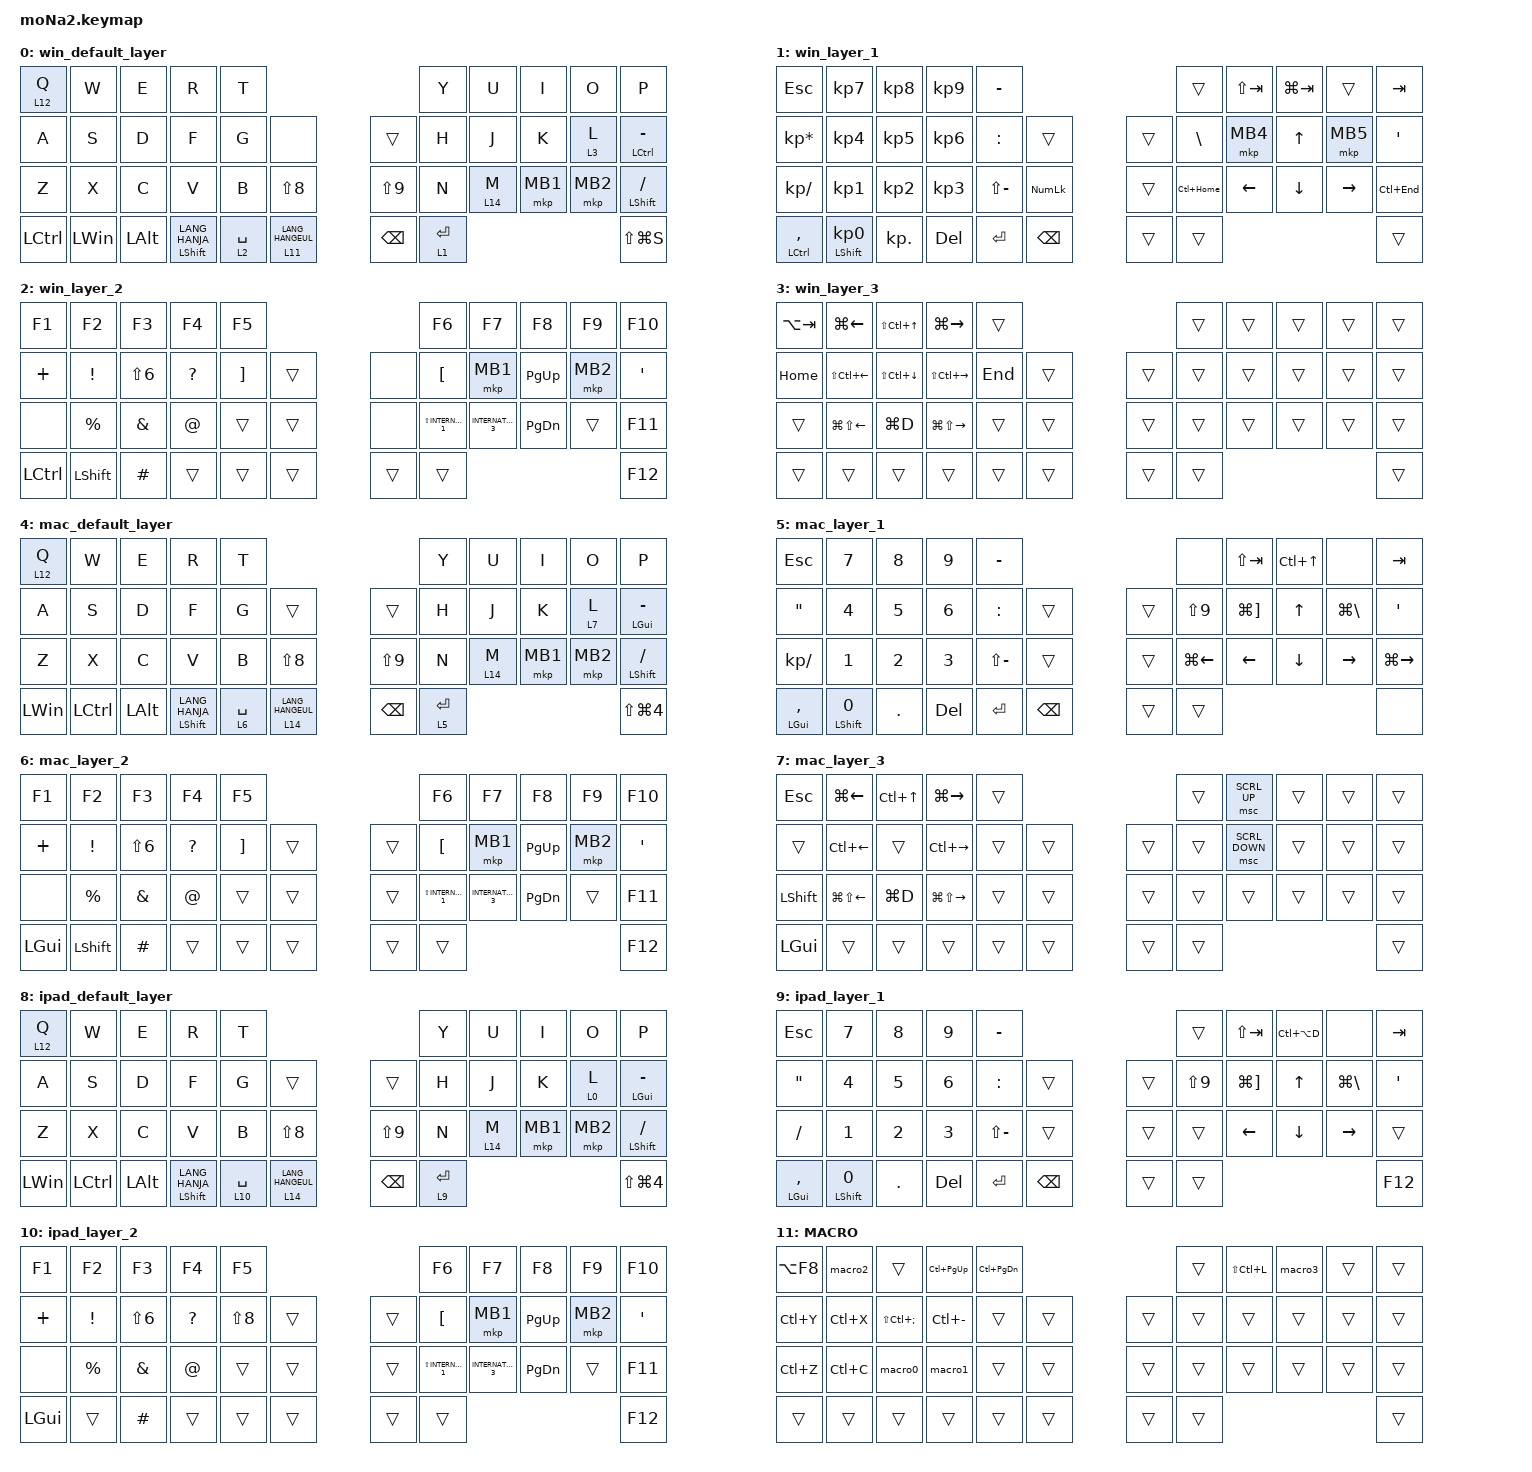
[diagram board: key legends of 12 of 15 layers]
//#include "layout_shift.dtsi"

#include <layout_shift_kp_override.dtsi>
#include <behaviors.dtsi>
#include <dt-bindings/zmk/bt.h>
#include <dt-bindings/zmk/keys.h>
#include <dt-bindings/zmk/pointing.h>

#define ZMK_POINTING_DEFAULT_SCRL_VAL 100
#define MOUSE 13

&mt {
    flavor = "balanced";
    quick-tap-ms = <0>;
};

&sl { release-after-ms = <250>; }; // ダブルクリックに必要な時間を設定
/ {
    combos {
        compatible = "zmk,combos";

        alt+ctrl+del {
            bindings = <&kp LA(LC(DELETE))>;
            key-positions = <41 9>;
        };

        left_click {
            bindings = <&mkp LCLK>;
            key-positions = <18 19>;
        };

        right_click {
            bindings = <&mkp RCLK>;
            key-positions = <20 18>;
        };

        comma {
            bindings = <&kp COMMA>;
            key-positions = <30 31>;
        };

        period {
            bindings = <&kp PERIOD>;
            key-positions = <31 32>;
        };
    };

    macros {
        to_layer_0: to_layer_0 {
            compatible = "zmk,behavior-macro-one-param";
            #binding-cells = <1>;
            bindings = <&to 0 &macro_param_1to1 &kp MACRO_PLACEHOLDER>;
            label = "TO_LAYER_0";
        };

        macro0: macro0 {
            compatible = "zmk,behavior-macro";
            #binding-cells = <0>;
            bindings = <&kp LA(LC(V)) &kp V &kp ENTER>;
            label = "MACRO1";
        };

        macro1: macro1 {
            compatible = "zmk,behavior-macro";
            #binding-cells = <0>;
            bindings = <&kp LA(H) &kp M &kp C &kp ENTER>;
            label = "MACRO2";
        };

        macro2: macro2 {
            compatible = "zmk,behavior-macro";
            #binding-cells = <0>;
            bindings = <&kp LC(G) &kp LA(S) &kp K &kp ENTER>;
            label = "MACRO3";
        };

        macro3: macro3 {
            compatible = "zmk,behavior-macro";
            #binding-cells = <0>;
            bindings = <&kp LEFT_ALT &kp D &kp F &kp S>;
            label = "MACRO0";
        };

        mkp_exit_AML: mkp_exit_AML {
            compatible = "zmk,behavior-macro-one-param";
            #binding-cells = <1>;
            bindings =
                <&macro_press>,
                <&macro_param_1to1 &mkp MACRO_PLACEHOLDER>,
                <&macro_pause_for_release>,
                <&macro_release>,
                <&macro_param_1to1 &mkp MACRO_PLACEHOLDER>,
                <&macro_tap>,
                <&sl 13>;

            label = "MKP_EXIT_AML";
        };

        bt0: bt0 {
            compatible = "zmk,behavior-macro";
            #binding-cells = <0>;
            bindings =
                <&tog_off 4 &tog_off 8>,
                <&macro_wait_time 200>,
                <&bt BT_SEL 0>,
                <&macro_wait_time 500>,
                <&bt BT_DISC 1 &bt BT_DISC 2>;

            label = "BT0";
        };

        bt1: bt1 {
            compatible = "zmk,behavior-macro";
            #binding-cells = <0>;
            bindings =
                <&tog_off 0 &tog_off 4 &tog_off 8>,
                <&macro_wait_time 200>,
                <&bt BT_SEL 1>,
                <&macro_wait_time 500>,
                <&tog_on 4 &bt BT_DISC 0 &bt BT_DISC 2>;

            label = "BT1";
        };

        bt2: bt2 {
            compatible = "zmk,behavior-macro";
            #binding-cells = <0>;
            bindings =
                <&tog_off 0 &tog_off 4 &tog_off 8>,
                <&macro_wait_time 200>,
                <&bt BT_SEL 2>,
                <&macro_wait_time 500>,
                <&tog_on 8 &bt BT_DISC 0 &bt BT_DISC 1>;

            label = "BT2";
        };

        macro4_copy_lay15: macro_4 {
            compatible = "zmk,behavior-macro";
            #binding-cells = <0>;
            bindings = <&kp LS(LC(DOWN_ARROW)) &kp LS(LC(RIGHT_ARROW)) &kp LS(LC(RIGHT_ARROW)) &kp LC(C)>;
            label = "MACRO_4";
        };

        macro_5_copy_lay15: macro_5 {
            compatible = "zmk,behavior-macro";
            #binding-cells = <0>;
            bindings = <&kp LS(LC(RIGHT_ARROW)) &kp LS(LC(RIGHT_ARROW)) &kp LC(C)>;
            label = "MACRO_5";
        };

        macro_6_ketsugou_lay15: macro_6 {
            compatible = "zmk,behavior-macro";
            #binding-cells = <0>;
            bindings = <&kp LS(LC(DOWN_ARROW)) &kp LA(H) &kp M &kp C &kp ENTER>;
            label = "MACRO_6";
        };
    };

    behaviors {
        lt_to_layer_0: lt_to_layer_0 {
            compatible = "zmk,behavior-hold-tap";
            label = "LAYER_TAP_TO_0";
            bindings = <&mo>, <&to_layer_0>;

            #binding-cells = <2>;
            tapping-term-ms = <200>;
        };

        scroll_up_down: behavior_sensor_rotate_mouse_wheel_up_down {
            compatible = "zmk,behavior-sensor-rotate";
            #sensor-binding-cells = <0>;
            bindings = <&msc SCRL_DOWN>, <&msc SCRL_UP>;

            tap-ms = <20>;
        };

        scroll_right_left: mouse_wheel_right_left {
            compatible = "zmk,behavior-sensor-rotate";
            #sensor-binding-cells = <0>;
            bindings = <&msc SCRL_LEFT>, <&msc SCRL_RIGHT>;

            tap-ms = <20>;
        };

        tog_on: toggle_layer_on_only {
            compatible = "zmk,behavior-toggle-layer";
            #binding-cells = <1>;
            display-name = "Toggle Layer On";
            toggle-mode = "on";
        };

        tog_off: toggle_layer_off_only {
            compatible = "zmk,behavior-toggle-layer";
            #binding-cells = <1>;
            display-name = "Toggle Layer Off";
            toggle-mode = "off";
        };

        // Keep the original key_press behavior for ZMK core components

        original_key_press: original_key_press {
            compatible = "zmk,behavior-key-press";
            #binding-cells = <1>;
            label = "KEY_PRESS";
        };

        // Override the existing &kp behavior to use our custom implementation

        kp: key_press {
            compatible = "zmk,behavior-layout-shift-key-press";
            #binding-cells = <1>;
            label = "LAYOUT_SHIFT_KEY_PRESS";
        };

        // Layout shift toggle behaviors

        tog_ls: toggle_layout_shift {
            compatible = "zmk,behavior-layout-shift-toggle";
            #binding-cells = <0>;
            toggle-mode = "flip";
            label = "LAYOUT_SHIFT_TOGGLE";
        };

        tog_ls_on: toggle_layout_shift_on {
            compatible = "zmk,behavior-layout-shift-toggle";
            #binding-cells = <0>;
            toggle-mode = "on";
            label = "LAYOUT_SHIFT_TOGGLE_ON";
        };

        tog_ls_off: toggle_layout_shift_off {
            compatible = "zmk,behavior-layout-shift-toggle";
            #binding-cells = <0>;
            toggle-mode = "off";
            label = "LAYOUT_SHIFT_TOGGLE_OFF";
        };
    };

    keymap {
        compatible = "zmk,keymap";

        win_default_layer {
            bindings = <
&lt 12 Q   &kp W         &kp E         &kp R                      &kp T                                                         &kp Y        &kp U     &kp I     &kp O     &kp P
&kp A      &kp S         &kp D         &kp F                      &kp G        &none                             &trans         &kp H        &kp J     &kp K     &lt 3 L   &mt LCTRL MINUS
&kp Z      &kp X         &kp C         &kp V                      &kp B        &kp LS(N8)                        &kp LS(N9)     &kp N        &lt 14 M  &mkp MB1  &mkp MB2  &mt LEFT_SHIFT SLASH
&kp LCTRL  &kp LEFT_WIN  &kp LEFT_ALT  &mt LEFT_SHIFT LANG_HANJA  &lt 2 SPACE  &lt_to_layer_0 11 LANG_HANGEUL    &kp BACKSPACE  &lt 1 ENTER                                &kp LS(LG(S))
            >;

            sensor-bindings = <&scroll_up_down>;
        };

        win_layer_1 {
            bindings = <
&kp ESCAPE       &kp KP_NUMBER_7             &kp KP_NUMBER_8  &kp KP_NUMBER_9  &kp MINUS                                &trans         &kp LS(TAB)     &kp LG(TAB)     &trans           &kp TAB
&kp KP_ASTERISK  &kp KP_NUMBER_4             &kp KP_NUMBER_5  &kp KP_NUMBER_6  &kp COLON      &trans            &trans  &kp BACKSLASH  &mkp MB4        &kp UP_ARROW    &mkp MB5         &kp SINGLE_QUOTE
&kp KP_SLASH     &kp KP_NUMBER_1             &kp KP_NUMBER_2  &kp KP_NUMBER_3  &kp LS(MINUS)  &kp KP_NUMLOCK    &trans  &kp LC(HOME)   &kp LEFT_ARROW  &kp DOWN_ARROW  &kp RIGHT_ARROW  &kp LC(END)
&mt LCTRL COMMA  &mt LEFT_SHIFT KP_NUMBER_0  &kp KP_DOT       &kp DEL          &kp ENTER      &kp BACKSPACE     &trans  &trans                                                          &trans
            >;

            sensor-bindings = <&scroll_right_left>;
        };

        win_layer_2 {
            bindings = <
&kp F1     &kp F2           &kp F3            &kp F4        &kp F5                               &kp F6                   &kp F7               &kp F8         &kp F9    &kp F10
&kp PLUS   &kp EXCLAMATION  &kp LS(NUMBER_6)  &kp QUESTION  &kp RIGHT_BRACKET  &trans    &none   &kp LEFT_BRACKET         &mkp MB1             &kp PAGE_UP    &mkp MB2  &kp SINGLE_QUOTE
&none      &kp PERCENT      &kp AMPERSAND     &kp AT_SIGN   &trans             &trans    &none   &kp LS(INTERNATIONAL_1)  &kp INTERNATIONAL_3  &kp PAGE_DOWN  &trans    &kp F11
&kp LCTRL  &kp LEFT_SHIFT   &kp POUND         &trans        &trans             &trans    &trans  &trans                                                                 &kp F12
            >;

            sensor-bindings = <&scroll_up_down>;
        };

        win_layer_3 {
            bindings = <
&kp LA(TAB)  &kp LG(LEFT_ARROW)      &kp LS(LC(UP_ARROW))    &kp LG(RIGHT_ARROW)      &trans                     &trans  &trans  &trans  &trans  &trans
&kp HOME     &kp LS(LC(LEFT_ARROW))  &kp LS(LC(DOWN_ARROW))  &kp LS(LC(RIGHT_ARROW))  &kp END  &trans    &trans  &trans  &trans  &trans  &trans  &trans
&trans       &kp LG(LS(LEFT_ARROW))  &kp LG(D)               &kp LG(LS(RIGHT_ARROW))  &trans   &trans    &trans  &trans  &trans  &trans  &trans  &trans
&trans       &trans                  &trans                  &trans                   &trans   &trans    &trans  &trans                          &trans
            >;

            sensor-bindings = <&scroll_up_down>;
        };

        mac_default_layer {
            bindings = <
&lt 12 Q      &kp W      &kp E         &kp R                      &kp T                                              &kp Y        &kp U     &kp I     &kp O     &kp P
&kp A         &kp S      &kp D         &kp F                      &kp G        &trans                 &trans         &kp H        &kp J     &kp K     &lt 7 L   &mt LEFT_GUI MINUS
&kp Z         &kp X      &kp C         &kp V                      &kp B        &kp LS(N8)             &kp LS(N9)     &kp N        &lt 14 M  &mkp MB1  &mkp MB2  &mt LEFT_SHIFT SLASH
&kp LEFT_WIN  &kp LCTRL  &kp LEFT_ALT  &mt LEFT_SHIFT LANG_HANJA  &lt 6 SPACE  &lt 14 LANG_HANGEUL    &kp BACKSPACE  &lt 5 ENTER                                &kp LS(LG(NUMBER_4))
            >;

            sensor-bindings = <&scroll_up_down>;
        };

        mac_layer_1 {
            bindings = <
&kp ESCAPE          &kp N7                   &kp NUMBER_8  &kp NUMBER_9  &kp MINUS                               &none               &kp LS(TAB)            &kp LC(UP_ARROW)  &none              &kp TAB
&kp DOUBLE_QUOTES   &kp NUMBER_4             &kp N5        &kp NUMBER_6  &kp COLON      &trans           &trans  &kp LS(NUMBER_9)    &kp LG(RIGHT_BRACKET)  &kp UP_ARROW      &kp LG(BACKSLASH)  &kp SINGLE_QUOTE
&kp KP_SLASH        &kp NUMBER_1             &kp NUMBER_2  &kp NUMBER_3  &kp LS(MINUS)  &trans           &trans  &kp LG(LEFT_ARROW)  &kp LEFT_ARROW         &kp DOWN_ARROW    &kp RIGHT_ARROW    &kp LG(RIGHT_ARROW)
&mt LEFT_GUI COMMA  &mt LEFT_SHIFT NUMBER_0  &kp PERIOD    &kp DEL       &kp ENTER      &kp BACKSPACE    &trans  &trans                                                                          &none
            >;

            sensor-bindings = <&scroll_up_down>;
        };

        mac_layer_2 {
            bindings = <
&kp F1        &kp F2           &kp F3            &kp F4        &kp F5                               &kp F6                   &kp F7               &kp F8         &kp F9    &kp F10
&kp PLUS      &kp EXCLAMATION  &kp LS(NUMBER_6)  &kp QUESTION  &kp RIGHT_BRACKET  &trans    &trans  &kp LEFT_BRACKET         &mkp MB1             &kp PAGE_UP    &mkp MB2  &kp SINGLE_QUOTE
&none         &kp PERCENT      &kp AMPERSAND     &kp AT_SIGN   &trans             &trans    &trans  &kp LS(INTERNATIONAL_1)  &kp INTERNATIONAL_3  &kp PAGE_DOWN  &trans    &kp F11
&kp LEFT_GUI  &kp LEFT_SHIFT   &kp POUND         &trans        &trans             &trans    &trans  &trans                                                                 &kp F12
            >;

            sensor-bindings = <&scroll_up_down>;
        };

        mac_layer_3 {
            bindings = <
&kp ESCAPE      &kp LG(LEFT_ARROW)      &kp LC(UP_ARROW)  &kp LG(RIGHT_ARROW)      &trans                    &trans  &msc SCRL_UP    &trans  &trans  &trans
&trans          &kp LC(LEFT_ARROW)      &trans            &kp LC(RIGHT_ARROW)      &trans  &trans    &trans  &trans  &msc SCRL_DOWN  &trans  &trans  &trans
&kp LEFT_SHIFT  &kp LG(LS(LEFT_ARROW))  &kp LG(D)         &kp LG(LS(RIGHT_ARROW))  &trans  &trans    &trans  &trans  &trans          &trans  &trans  &trans
&kp LEFT_GUI    &trans                  &trans            &trans                   &trans  &trans    &trans  &trans                                  &trans
            >;

            sensor-bindings = <&scroll_up_down>;
        };

        ipad_default_layer {
            bindings = <
&lt 12 Q      &kp W      &kp E         &kp R                      &kp T                                               &kp Y        &kp U     &kp I     &kp O     &kp P
&kp A         &kp S      &kp D         &kp F                      &kp G         &trans                 &trans         &kp H        &kp J     &kp K     &lt 0 L   &mt LEFT_GUI MINUS
&kp Z         &kp X      &kp C         &kp V                      &kp B         &kp LS(N8)             &kp LS(N9)     &kp N        &lt 14 M  &mkp MB1  &mkp MB2  &mt LEFT_SHIFT SLASH
&kp LEFT_WIN  &kp LCTRL  &kp LEFT_ALT  &mt LEFT_SHIFT LANG_HANJA  &lt 10 SPACE  &lt 14 LANG_HANGEUL    &kp BACKSPACE  &lt 9 ENTER                                &kp LS(LG(NUMBER_4))
            >;

            sensor-bindings = <&scroll_up_down>;
        };

        ipad_layer_1 {
            bindings = <
&kp ESCAPE          &kp N7                   &kp NUMBER_8  &kp NUMBER_9  &kp MINUS                               &trans            &kp LS(TAB)            &kp LC(LA(D))   &none              &kp TAB
&kp DOUBLE_QUOTES   &kp NUMBER_4             &kp N5        &kp NUMBER_6  &kp COLON      &trans           &trans  &kp LS(NUMBER_9)  &kp LG(RIGHT_BRACKET)  &kp UP_ARROW    &kp LG(BACKSLASH)  &kp SINGLE_QUOTE
&kp SLASH           &kp NUMBER_1             &kp NUMBER_2  &kp NUMBER_3  &kp LS(MINUS)  &trans           &trans  &trans            &kp LEFT_ARROW         &kp DOWN_ARROW  &kp RIGHT_ARROW    &trans
&mt LEFT_GUI COMMA  &mt LEFT_SHIFT NUMBER_0  &kp PERIOD    &kp DEL       &kp ENTER      &kp BACKSPACE    &trans  &trans                                                                      &kp F12
            >;

            sensor-bindings = <&scroll_up_down>;
        };

        ipad_layer_2 {
            bindings = <
&kp F1        &kp F2           &kp F3            &kp F4        &kp F5                        &kp F6                   &kp F7               &kp F8         &kp F9    &kp F10
&kp PLUS      &kp EXCLAMATION  &kp LS(NUMBER_6)  &kp QUESTION  &kp LS(N8)  &trans    &trans  &kp LEFT_BRACKET         &mkp MB1             &kp PAGE_UP    &mkp MB2  &kp SINGLE_QUOTE
&none         &kp PERCENT      &kp AMPERSAND     &kp AT_SIGN   &trans      &trans    &trans  &kp LS(INTERNATIONAL_1)  &kp INTERNATIONAL_3  &kp PAGE_DOWN  &trans    &kp F11
&kp LEFT_GUI  &trans           &kp POUND         &trans        &trans      &trans    &trans  &trans                                                                 &kp F12
            >;

            sensor-bindings = <&scroll_up_down>;
        };

        MACRO {
            bindings = <
&kp LA(F8)  &macro2    &trans            &kp LC(PAGE_UP)  &kp LC(PAGE_DOWN)                    &trans  &kp LS(LC(L))  &macro3  &trans  &trans
&kp LC(Y)   &kp LC(X)  &kp LS(LC(SEMI))  &kp LC(MINUS)    &trans             &trans    &trans  &trans  &trans         &trans   &trans  &trans
&kp LC(Z)   &kp LC(C)  &macro0           &macro1          &trans             &trans    &trans  &trans  &trans         &trans   &trans  &trans
&trans      &trans     &trans            &trans           &trans             &trans    &trans  &trans                                  &trans
            >;

            sensor-bindings = <&scroll_up_down>;
        };

        bt_setting_layer {
            bindings = <
&trans  &trans  &trans  &tog_ls      &trans                              &bt0    &bt1          &bt2          &bt BT_SEL 3  &bt BT_SEL 4
&trans  &trans  &trans  &tog_ls_on   &trans  &trans         &trans       &trans  &kp C_BRI_UP  &kp C_VOL_UP  &trans        &trans
&trans  &trans  &trans  &tog_ls_off  &trans  &bootloader    &bootloader  &trans  &kp C_BRI_DN  &kp C_VOL_DN  &trans        &bt BT_CLR
&trans  &trans  &trans  &trans       &trans  &trans         &trans       &trans                                            &bt BT_CLR_ALL
            >;

            sensor-bindings = <&scroll_up_down>;
        };

        MOUSE {
            bindings = <
&trans  &trans  &trans  &trans  &trans                    &trans  &trans              &trans  &trans              &trans
&trans  &trans  &trans  &trans  &trans  &trans    &trans  &trans  &mkp_exit_AML LCLK  &trans  &mkp_exit_AML RCLK  &trans
&trans  &trans  &trans  &trans  &trans  &trans    &trans  &trans  &trans              &trans  &trans              &trans
&trans  &trans  &trans  &trans  &trans  &trans    &trans  &trans                                                  &trans
            >;

            sensor-bindings = <&scroll_up_down>;
        };

        scroll_layer {
            bindings = <
&trans  &trans  &trans  &trans  &trans                    &trans  &trans  &trans  &trans  &trans
&trans  &trans  &trans  &trans  &trans  &trans    &trans  &trans  &trans  &trans  &trans  &trans
&trans  &trans  &trans  &trans  &trans  &trans    &trans  &trans  &trans  &trans  &trans  &trans
&trans  &trans  &trans  &trans  &trans  &trans    &trans  &trans                          &trans
            >;

            sensor-bindings = <&scroll_up_down>;
        };
    };
};
